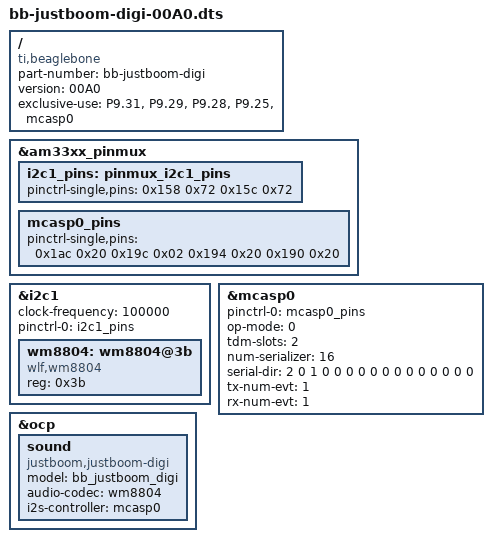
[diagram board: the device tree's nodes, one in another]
/*
 * Copyright (C) 2012 Texas Instruments Incorporated - http://www.ti.com/
 *
 * This program is free software; you can redistribute it and/or modify
 * it under the terms of the GNU General Public License version 2 as
 * published by the Free Software Foundation.
 */
/dts-v1/;
/plugin/;

/ {
	compatible = "ti,beaglebone", "ti,beaglebone-black";

	/* identification */
	part-number = "bb-justboom-digi";
	version = "00A0";

	/* state the resources this cape uses */
	exclusive-use =
		/* the pin header uses */
		"P9.31",	/* mcasp0: mcasp0_aclkx */
		"P9.29",	/* mcasp0: mcasp0_fsx */
		"P9.28",	/* mcasp0: mcasp0_axr2 */
		"P9.25",	/* mcasp0: mcasp0_ahclkx */
		/* the hardware ip uses */
		"mcasp0";

	fragment@0 {
		target = <&am33xx_pinmux>;
		__overlay__ {

			i2c1_pins: pinmux_i2c1_pins {
				pinctrl-single,pins = <
					0x158 0x72 	/*spi0_d1.i2c1_sda,SLEWCTRL_SLOW | INPUT_PULLUP |MODE2*/
					0x15c 0x72	/*spi0_cs0.i2c1_scl,SLEWCTRL_SLOW | INPUT_PULLUP | MODE2*/
				>;
			};

			mcasp0_pins: mcasp0_pins {
				pinctrl-single,pins = <
					0x1ac 0x20      /* mcasp0_ahclkx,             MODE0 | INPUT_PULLDOWN */
					0x19c 0x02		/* mcasp0_ahclkr, 			  MODE2 | OUTPUT_PULLDOWN */
					0x194 0x20      /* mcasp0_fsx,         	      MODE0 | INPUT_PULLDOWN  */
					0x190 0x20      /* mcasp0_aclkr.mcasp0_aclkx, MODE0 | INPUT_PULLDOWN */ 
				>;
			};
		};
	};

	fragment@1 {
		target = <&i2c1>;
		__overlay__ {
			#address-cells = <1>;
			#size-cells = <0>;
			clock-frequency = <100000>;
			status = "okay";
			pinctrl-names = "default";
			pinctrl-0 = <&i2c1_pins>;

			wm8804: wm8804@3b {
				#sound-dai-cells = <0>;
				compatible = "wlf,wm8804";
				reg = <0x3b>;
				/*PVDD-supply = <&vdd_3v3_reg>;
				DVDD-supply = <&vdd_3v3_reg>;*/
				status = "okay";
			};
		};
	};

	fragment@2 {
		target = <&mcasp0>;
		__overlay__ {
			pinctrl-names = "default";
			pinctrl-0 = <&mcasp0_pins>;

			status = "okay";

			op-mode = <0>;          /* MCASP_IIS_MODE */
			tdm-slots = <2>;
			num-serializer = <16>;
			serial-dir = <  /* 0: INACTIVE, 1: TX, 2: RX */
				2 0 1 0
				0 0 0 0
				0 0 0 0
				0 0 0 0
			>;
			tx-num-evt = <1>;
			rx-num-evt = <1>;
		};
	};

	fragment@3 {
		target = <&ocp>;
		__overlay__ {
			sound {
				compatible = "justboom,justboom-digi";
				model = "bb_justboom_digi";
				audio-codec = <&wm8804>;
				i2s-controller = <&mcasp0>;
			};
		};

	};
};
